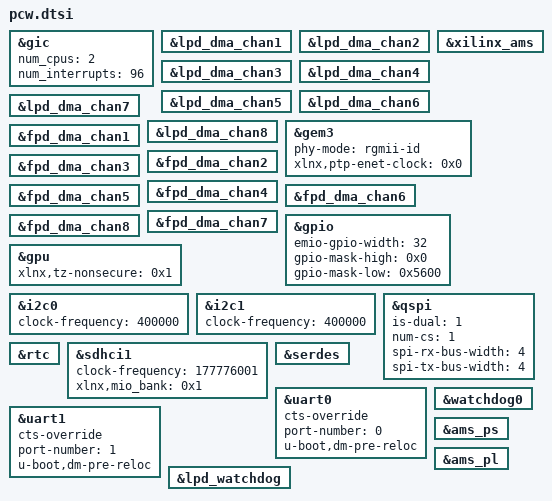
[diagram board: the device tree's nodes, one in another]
/*
 * CAUTION: This file is automatically generated by Xilinx.
 * Version:  
 * Today is: Wed Dec 14 13:36:20 2022
 */


&gic {
	num_cpus = <2>;
	num_interrupts = <96>;
};
&lpd_dma_chan1 {
	status = "okay";
};
&lpd_dma_chan2 {
	status = "okay";
};
&lpd_dma_chan3 {
	status = "okay";
};
&lpd_dma_chan4 {
	status = "okay";
};
&lpd_dma_chan5 {
	status = "okay";
};
&lpd_dma_chan6 {
	status = "okay";
};
&lpd_dma_chan7 {
	status = "okay";
};
&lpd_dma_chan8 {
	status = "okay";
};
&xilinx_ams {
	status = "okay";
};
&gem3 {
	phy-mode = "rgmii-id";
	status = "okay";
	xlnx,ptp-enet-clock = <0x0>;
};
&fpd_dma_chan1 {
	status = "okay";
};
&fpd_dma_chan2 {
	status = "okay";
};
&fpd_dma_chan3 {
	status = "okay";
};
&fpd_dma_chan4 {
	status = "okay";
};
&fpd_dma_chan5 {
	status = "okay";
};
&fpd_dma_chan6 {
	status = "okay";
};
&fpd_dma_chan7 {
	status = "okay";
};
&fpd_dma_chan8 {
	status = "okay";
};
&gpio {
	emio-gpio-width = <32>;
	gpio-mask-high = <0x0>;
	gpio-mask-low = <0x5600>;
	status = "okay";
};
&gpu {
	status = "okay";
	xlnx,tz-nonsecure = <0x1>;
};
&i2c0 {
	clock-frequency = <400000>;
	status = "okay";
};
&i2c1 {
	clock-frequency = <400000>;
	status = "okay";
};
&qspi {
	is-dual = <1>;
	num-cs = <1>;
	spi-rx-bus-width = <4>;
	spi-tx-bus-width = <4>;
	status = "okay";
};
&rtc {
	status = "okay";
};
&sdhci1 {
	clock-frequency = <177776001>;
	status = "okay";
	xlnx,mio_bank = <0x1>;
};
&serdes {
	status = "okay";
};
&uart0 {
	cts-override ;
	device_type = "serial";
	port-number = <0>;
	status = "okay";
	u-boot,dm-pre-reloc ;
};
&uart1 {
	cts-override ;
	device_type = "serial";
	port-number = <1>;
	status = "okay";
	u-boot,dm-pre-reloc ;
};
&lpd_watchdog {
	status = "okay";
};
&watchdog0 {
	status = "okay";
};
&ams_ps {
	status = "okay";
};
&ams_pl {
	status = "okay";
};
